AUTOSAR XML (schema 4-3-0)
package /ComponentTypes
  swc implementation CtSaWindow_Implementation: behavior=CtSaWindow_InternalBehavior
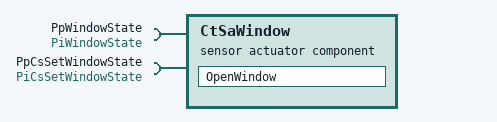
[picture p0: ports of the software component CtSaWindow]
  sensor actuator sw component type CtSaWindow
    require port PpWindowState: nonqueued-receiver-com-spec=data-element=DeWindowState, required-interface=PiWindowState
    require port PpCsSetWindowState: required-com-specs=[Operation, WriteToWindow], required-interface=PiCsSetWindowState
    behavior CtSaWindow_InternalBehavior
      data received event DRT_OpenWindow_PpWindowState_DeWindowState: start-on-event=OpenWindow, data=PpWindowState.DeWindowState
      runnable OpenWindow
        internal triggering point ITP_OpenWindow
        sync call SC_PpCsSetWindowState_WriteToWindow: operation=PpCsSetWindowState.WriteToWindow
